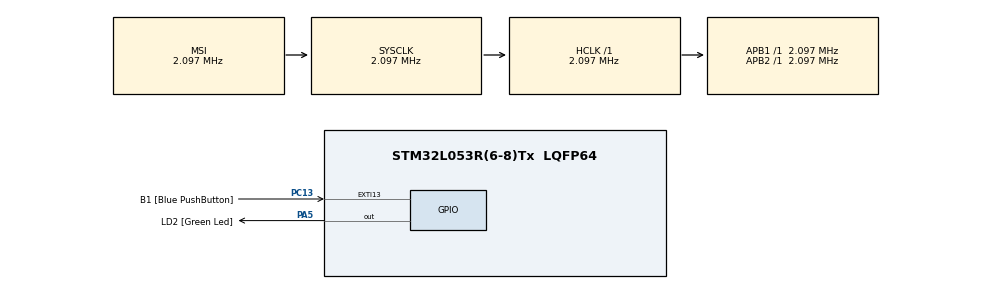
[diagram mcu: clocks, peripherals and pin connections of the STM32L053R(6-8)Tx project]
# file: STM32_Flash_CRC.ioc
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Mcu.Family=STM32L0
Mcu.Name=STM32L053R(6-8)Tx
Mcu.Package=LQFP64
PA13.GPIO_Label=TMS
PA13.Signal=SYS_SWDIO
PA14.GPIO_Label=TCK
PA14.Signal=SYS_SWCLK
PA2.GPIO_Label=USART_TX
PA2.Signal=USART2_TX
PA3.GPIO_Label=USART_RX
PA3.Signal=USART2_RX
PA5.GPIO_Label=LD2 [Green Led]
PA5.Signal=GPIO_Output
PC13.GPIO_Label=B1 [Blue PushButton]
PC13.GPIO_ModeDefaultEXTI=GPIO_MODE_IT_FALLING
PC13.Signal=GPXTI13
PC14-OSC32_IN.Signal=RCC_OSC32_IN
PC15-OSC32_OUT.Signal=RCC_OSC32_OUT
PH0-OSC_IN.Signal=RCC_OSC_IN
PH1-OSC_OUT.Signal=RCC_OSC_OUT
ProjectManager.HeapSize=0x200
ProjectManager.StackSize=0x400
ProjectManager.TargetToolchain=STM32CubeIDE
RCC.AHBFreq_Value=2097000
RCC.APB1Freq_Value=2097000
RCC.APB1TimFreq_Value=2097000
RCC.APB2Freq_Value=2097000
RCC.APB2TimFreq_Value=2097000
RCC.HSE_VALUE=8000000
RCC.HSI16_VALUE=16000000
RCC.HSI48_VALUE=48000000
RCC.HSI_VALUE=16000000
RCC.LSEState=RCC_LSE_ON
RCC.LSE_VALUE=32768
RCC.MSI_VALUE=2097000
RCC.SYSCLKFreq_VALUE=2097000
RCC.VCOOutputFreq_Value=48000000
VP_CRC_VS_CRC.Mode=CRC_Activate
board=NUCLEO-L053R8

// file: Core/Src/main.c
/* USER CODE BEGIN Header */
/**
  ******************************************************************************
  * @file           : main.c
  * @brief          : Main program body
  ******************************************************************************
  * @attention
  *
  * Copyright (c) 2023 STMicroelectronics.
  * All rights reserved.
  *
  * This software is licensed under terms that can be found in the LICENSE file
  * in the root directory of this software component.
  * If no LICENSE file comes with this software, it is provided AS-IS.
  *
  ******************************************************************************
  */
/* USER CODE END Header */
#include "main.h"

CRC_HandleTypeDef hcrc;

void SystemClock_Config(void);
static void MX_GPIO_Init(void);
static void MX_CRC_Init(void);

/* USER CODE BEGIN 0 */

// There is a good explanation at https://sourceware.org/binutils/docs/ld/Source-Code-Reference.html
// __image_crc_addr is a linker script(.ld) variable that stores a memory location
// The variable is set by the linker during the linking process
// By "set" we mean that it exists in the symbol table but no memory is allocated for it
// The variable's value is the "address" it points to in the symbol table
// Our goal is to read the value of the linker script variable

extern char __image_crc_addr;

uint32_t GetStoredCRC(){

	uint32_t *flash_crc = &__image_crc_addr;

	return *flash_crc;
}
/* USER CODE END 0 */

int main(void)
{

  /* MCU Configuration--------------------------------------------------------*/

  /* Reset of all peripherals, Initializes the Flash interface and the Systick. */
  HAL_Init();

  /* Configure the system clock */
  SystemClock_Config();

  /* Initialize all configured peripherals */
  MX_GPIO_Init();
  MX_CRC_Init();
  /* USER CODE BEGIN 2 */

  uint32_t crc = GetStoredCRC();
  uint32_t default_crc = 0x5CA1AB1E;

//  if (default_crc == *crc) {
//
//  }
  /* USER CODE END 2 */

  /* Infinite loop */
  while (1)
  {
	  HAL_Delay(500);
	  HAL_GPIO_TogglePin(LD2_GPIO_Port, LD2_Pin);

  }
}

void SystemClock_Config(void)
{
  RCC_OscInitTypeDef RCC_OscInitStruct = {0};
  RCC_ClkInitTypeDef RCC_ClkInitStruct = {0};

  /** Configure the main internal regulator output voltage
  */
  __HAL_PWR_VOLTAGESCALING_CONFIG(PWR_REGULATOR_VOLTAGE_SCALE1);

  /** Initializes the RCC Oscillators according to the specified parameters
  * in the RCC_OscInitTypeDef structure.
  */
  RCC_OscInitStruct.OscillatorType = RCC_OSCILLATORTYPE_MSI;
  RCC_OscInitStruct.MSIState = RCC_MSI_ON;
  RCC_OscInitStruct.MSICalibrationValue = 0;
  RCC_OscInitStruct.MSIClockRange = RCC_MSIRANGE_5;
  RCC_OscInitStruct.PLL.PLLState = RCC_PLL_NONE;
  if (HAL_RCC_OscConfig(&RCC_OscInitStruct) != HAL_OK)
  {
    Error_Handler();
  }

  /** Initializes the CPU, AHB and APB buses clocks
  */
  RCC_ClkInitStruct.ClockType = RCC_CLOCKTYPE_HCLK|RCC_CLOCKTYPE_SYSCLK
                              |RCC_CLOCKTYPE_PCLK1|RCC_CLOCKTYPE_PCLK2;
  RCC_ClkInitStruct.SYSCLKSource = RCC_SYSCLKSOURCE_MSI;
  RCC_ClkInitStruct.AHBCLKDivider = RCC_SYSCLK_DIV1;
  RCC_ClkInitStruct.APB1CLKDivider = RCC_HCLK_DIV1;
  RCC_ClkInitStruct.APB2CLKDivider = RCC_HCLK_DIV1;

  if (HAL_RCC_ClockConfig(&RCC_ClkInitStruct, FLASH_LATENCY_0) != HAL_OK)
  {
    Error_Handler();
  }
}

static void MX_CRC_Init(void)
{

  hcrc.Instance = CRC;
  hcrc.Init.DefaultPolynomialUse = DEFAULT_POLYNOMIAL_ENABLE;
  hcrc.Init.DefaultInitValueUse = DEFAULT_INIT_VALUE_ENABLE;
  hcrc.Init.InputDataInversionMode = CRC_INPUTDATA_INVERSION_NONE;
  hcrc.Init.OutputDataInversionMode = CRC_OUTPUTDATA_INVERSION_DISABLE;
  hcrc.InputDataFormat = CRC_INPUTDATA_FORMAT_BYTES;
  if (HAL_CRC_Init(&hcrc) != HAL_OK)
  {
    Error_Handler();
  }

}

static void MX_GPIO_Init(void)
{
  GPIO_InitTypeDef GPIO_InitStruct = {0};

  /* GPIO Ports Clock Enable */
  __HAL_RCC_GPIOC_CLK_ENABLE();
  __HAL_RCC_GPIOH_CLK_ENABLE();
  __HAL_RCC_GPIOA_CLK_ENABLE();

  /*Configure GPIO pin Output Level */
  HAL_GPIO_WritePin(LD2_GPIO_Port, LD2_Pin, GPIO_PIN_RESET);

  /*Configure GPIO pin : B1_Pin */
  GPIO_InitStruct.Pin = B1_Pin;
  GPIO_InitStruct.Mode = GPIO_MODE_IT_FALLING;
  GPIO_InitStruct.Pull = GPIO_NOPULL;
  HAL_GPIO_Init(B1_GPIO_Port, &GPIO_InitStruct);

  /*Configure GPIO pins : USART_TX_Pin USART_RX_Pin */
  GPIO_InitStruct.Pin = USART_TX_Pin|USART_RX_Pin;
  GPIO_InitStruct.Mode = GPIO_MODE_AF_PP;
  GPIO_InitStruct.Pull = GPIO_NOPULL;
  GPIO_InitStruct.Speed = GPIO_SPEED_FREQ_VERY_HIGH;
  GPIO_InitStruct.Alternate = GPIO_AF4_USART2;
  HAL_GPIO_Init(GPIOA, &GPIO_InitStruct);

  /*Configure GPIO pin : LD2_Pin */
  GPIO_InitStruct.Pin = LD2_Pin;
  GPIO_InitStruct.Mode = GPIO_MODE_OUTPUT_PP;
  GPIO_InitStruct.Pull = GPIO_NOPULL;
  GPIO_InitStruct.Speed = GPIO_SPEED_FREQ_LOW;
  HAL_GPIO_Init(LD2_GPIO_Port, &GPIO_InitStruct);

}

void Error_Handler(void)
{
  __disable_irq();
  while (1)
  {
  }
}
